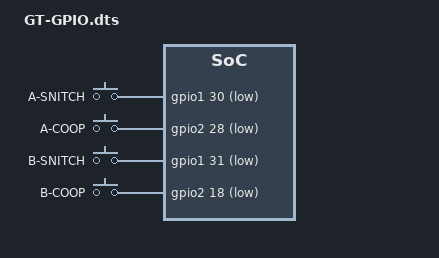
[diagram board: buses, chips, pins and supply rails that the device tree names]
/* 
* DTS for the MWL Prisoner's Dilemma Party
* Jon Newman
*/

/dts-v1/;
/plugin/;

/ {
    compatible = "ti,beaglebone", "ti,beaglebone-black";

    /* identification */
    part-number = "GT-GPIO";
    version = "00A0";

    fragment@0 {
        target = <&am33xx_pinmux>;
        __overlay__ {
            end_stop_pins: pinmux_end_stop_pins{
                pinctrl-single,pins = <
                    0x070 0x37 // P8_11 = GPIO0_30 = 30
                    0x078 0x37 // P9_12 = GPIO0_28 = 60
                    0x074 0x37 // P9_13 = GPIO0_31 = 31
                    0x048 0x37 // P9_14 = GPIO0_18 = 50
                >;
            };
        };
    };

    fragment@1 {
        target = <&ocp>;
        __overlay__ {            
            #address-cells = <1>;
            #size-cells = <1>;                            

            gpio_keys {
                compatible = "gpio-keys";
                pinctrl-names = "default";
                pinctrl-0 = <&end_stop_pins>;
                #address-cells = <1>;
                #size-cells = <0>;

                switch_ASNITCH {
                    label = "A-SNITCH";
                    debounce_interval = <50>;
                    linux,code = <1>;
                    gpios = <&gpio1 30 0x5>;
                    gpio-key,wakeup;
                };                
                switch_ACOOP {
                    label = "A-COOP";
                    debounce_interval = <50>;
                    linux,code = <2>;
                    gpios = <&gpio2 28 0x5>;
                    gpio-key,wakeup;
                };
                switch_BSNITCH {
                    label = "B-SNITCH";
                    debounce_interval = <50>;
                    linux,code = <3>;
                    gpios = <&gpio1 31 0x5>;
                    gpio-key,wakeup;
                };                
                switch_BCOOP {
                    label = "B-COOP";
                    debounce_interval = <50>;
                    linux,code = <4>;
                    gpios = <&gpio2 18 0x5>;
                    gpio-key,wakeup;
                };                    
            };
        };
    };
};
